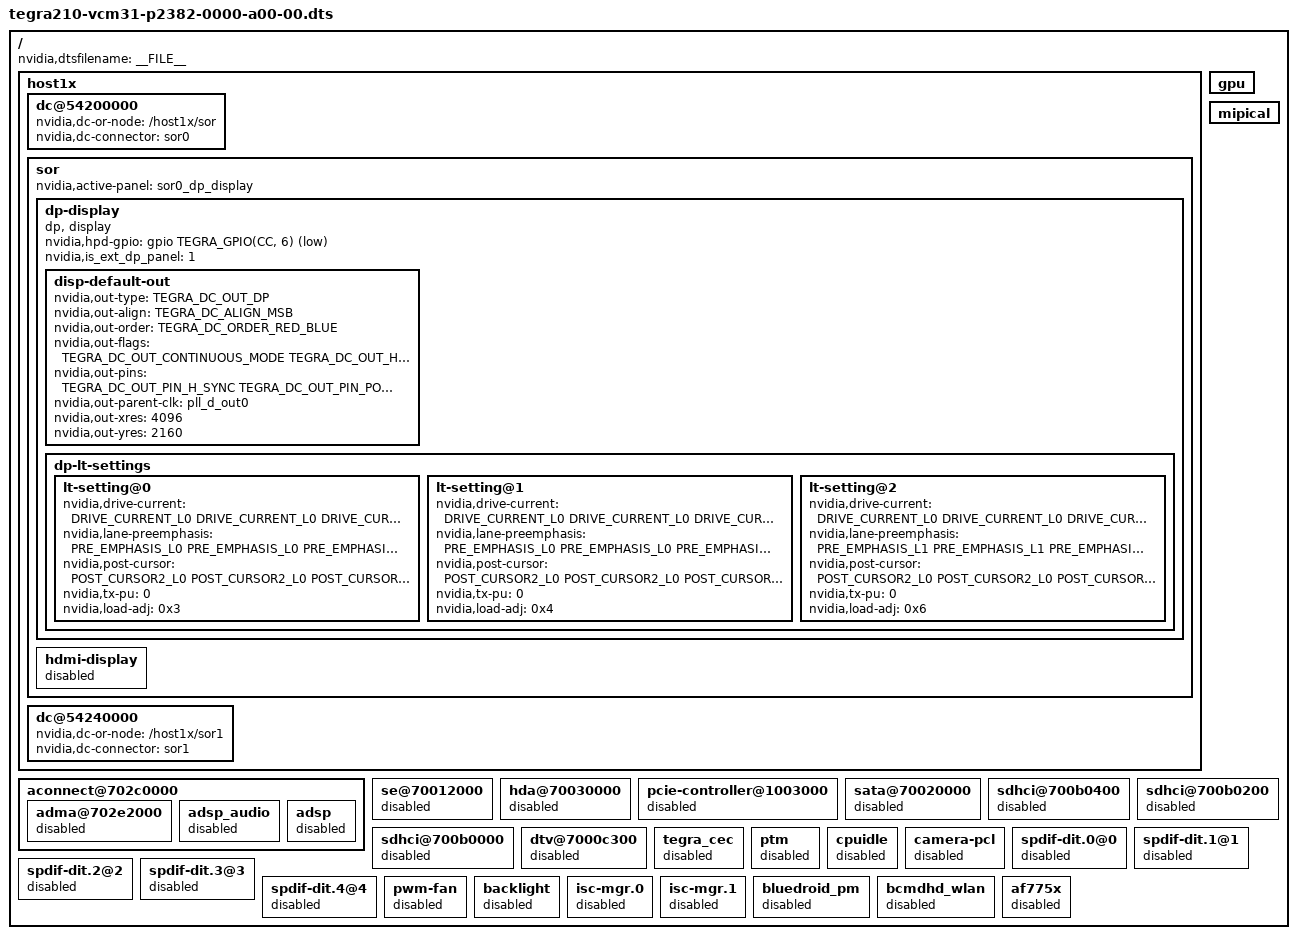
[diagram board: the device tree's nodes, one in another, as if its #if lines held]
/*
 * T210- VCM3.1
 *
 * arch/arm64/boot/dts/tegra210-vcm31-p2382-0000-a00-00.dts
 *
 * Copyright (c) 2015-2017, NVIDIA CORPORATION.  All rights reserved.
 *
 * This program is free software; you can redistribute it and/or modify
 * it under the terms of the GNU General Public License as published by
 * the Free Software Foundation; version 2 of the License.
 *
 * This program is distributed in the hope that it will be useful, but WITHOUT
 * ANY WARRANTY; without even the implied warranty of MERCHANTABILITY or
 * FITNESS FOR A PARTICULAR PURPOSE.  See the GNU General Public License for
 * more details.
 *
 * You should have received a copy of the GNU General Public License along
 * with this program; if not, write to the Free Software Foundation, Inc.,
 * 51 Franklin Street, Fifth Floor, Boston, MA  02110-1301, USA.
 *
 */

/dts-v1/;
/memreserve/ 0x80000000 0x00020000;

#include "tegra210-vcm31-p2382-common.dtsi"

/ {
	nvidia,dtsfilename = __FILE__;

	host1x {
		status = "okay";
		dc@54200000 {
			status = "okay";
			nvidia,dc-or-node = "/host1x/sor";
			nvidia,dc-connector = <&sor0>;
		};
		sor {
			status = "okay";
			nvidia,active-panel = <&sor0_dp_display>;
			dp-display {
				status = "okay";
				compatible = "dp, display";
				nvidia,hpd-gpio = <&gpio TEGRA_GPIO(CC, 6) 1>;
				nvidia,is_ext_dp_panel = <1>;
				disp-default-out {
					nvidia,out-type = <TEGRA_DC_OUT_DP>;
					nvidia,out-align = <TEGRA_DC_ALIGN_MSB>;
					nvidia,out-order = <TEGRA_DC_ORDER_RED_BLUE>;
					nvidia,out-flags = <TEGRA_DC_OUT_CONTINUOUS_MODE TEGRA_DC_OUT_HOTPLUG_HIGH>;
					nvidia,out-pins = <TEGRA_DC_OUT_PIN_H_SYNC TEGRA_DC_OUT_PIN_POL_LOW
							   TEGRA_DC_OUT_PIN_V_SYNC TEGRA_DC_OUT_PIN_POL_LOW
							   TEGRA_DC_OUT_PIN_PIXEL_CLOCK TEGRA_DC_OUT_PIN_POL_LOW
							   TEGRA_DC_OUT_PIN_DATA_ENABLE TEGRA_DC_OUT_PIN_POL_HIGH>;
					nvidia,out-parent-clk = "pll_d_out0";
					nvidia,out-xres = <4096>;
					nvidia,out-yres = <2160>;
				};
				dp-lt-settings {
					lt-setting@0 {
						nvidia,drive-current = <DRIVE_CURRENT_L0 DRIVE_CURRENT_L0 DRIVE_CURRENT_L0 DRIVE_CURRENT_L0>;
						nvidia,lane-preemphasis = <PRE_EMPHASIS_L0 PRE_EMPHASIS_L0 PRE_EMPHASIS_L0 PRE_EMPHASIS_L0>;
						nvidia,post-cursor = <POST_CURSOR2_L0 POST_CURSOR2_L0 POST_CURSOR2_L0 POST_CURSOR2_L0>;
						nvidia,tx-pu = <0>;
						nvidia,load-adj = <0x3>;
					};
					lt-setting@1 {
						nvidia,drive-current = <DRIVE_CURRENT_L0 DRIVE_CURRENT_L0 DRIVE_CURRENT_L0 DRIVE_CURRENT_L0>;
						nvidia,lane-preemphasis = <PRE_EMPHASIS_L0 PRE_EMPHASIS_L0 PRE_EMPHASIS_L0 PRE_EMPHASIS_L0>;
						nvidia,post-cursor = <POST_CURSOR2_L0 POST_CURSOR2_L0 POST_CURSOR2_L0 POST_CURSOR2_L0>;
						nvidia,tx-pu = <0>;
						nvidia,load-adj = <0x4>;
					};
					lt-setting@2 {
						nvidia,drive-current = <DRIVE_CURRENT_L0 DRIVE_CURRENT_L0 DRIVE_CURRENT_L0 DRIVE_CURRENT_L0>;
						nvidia,lane-preemphasis = <PRE_EMPHASIS_L1 PRE_EMPHASIS_L1 PRE_EMPHASIS_L1 PRE_EMPHASIS_L1>;
						nvidia,post-cursor = <POST_CURSOR2_L0 POST_CURSOR2_L0 POST_CURSOR2_L0 POST_CURSOR2_L0>;
						nvidia,tx-pu = <0>;
						nvidia,load-adj = <0x6>;
					};
				};
			};

			hdmi-display {
				status = "disabled";
			};
		};
		dc@54240000 {
			status = "okay";
			nvidia,dc-or-node = "/host1x/sor1";
			nvidia,dc-connector = <&sor1>;
		};
	};

	gpu {
		status = "okay";
	};

	mipical {
		status = "okay";
	};

#if TEGRA_AUDIO_BUS_DT_VERSION >= DT_VERSION_2
	aconnect@702c0000 {
#endif
	adma@702e2000 {
		status = "disabled";
	};
#if TEGRA_AUDIO_BUS_DT_VERSION >= DT_VERSION_2
	};
#endif

	se@70012000 {
		status = "disabled";
	};

	hda@70030000 {
		status = "disabled";
	};

#if TEGRA_AUDIO_BUS_DT_VERSION >= DT_VERSION_2
	aconnect@702c0000 {
#endif
	adsp_audio {
		status = "disabled";
	};

	adsp {
		status = "disabled";
	};
#if TEGRA_AUDIO_BUS_DT_VERSION >= DT_VERSION_2
	};
#endif

	pcie-controller@1003000 {
		status = "disabled";
	};

	sata@70020000 {
		status = "disabled";
	};


	sdhci@700b0400 {
		status = "disabled";
	};

	sdhci@700b0200 {
		status = "disabled";
	};

	sdhci@700b0000 {
		status = "disabled";
	};


	dtv@7000c300 {
		status = "disabled";
	};


	tegra_cec {
		status = "disabled";
	};

	ptm {
		status = "disabled";
	};

	cpuidle {
		status = "disabled";
	};

	camera-pcl {
		status = "disabled";
	};

	spdif-dit.0@0 {
		status = "disabled";
	};

	spdif-dit.1@1 {
		status = "disabled";
	};

	spdif-dit.2@2 {
		status = "disabled";
	};

	spdif-dit.3@3 {
		status = "disabled";
	};

	spdif-dit.4@4 {
		status = "disabled";
	};

	pwm-fan {
		status = "disabled";
	};

	backlight {
		status = "disabled";
	};

	isc-mgr.0 {
		status = "disabled";
	};

	isc-mgr.1 {
		status = "disabled";
	};

	bluedroid_pm {
		status = "disabled";
	};

	bcmdhd_wlan {
		status = "disabled";
	};

	af775x {
		status = "disabled";
	};

};
